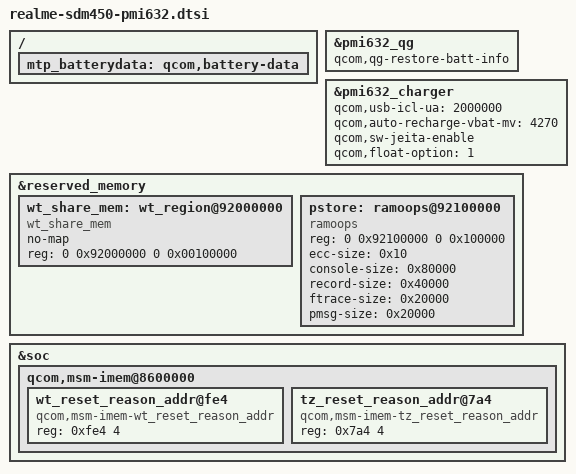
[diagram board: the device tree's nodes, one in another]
/*
 * Copyright (c) 2017-2018, The Linux Foundation. All rights reserved.
 *
 * This program is free software; you can redistribute it and/or modify
 * it under the terms of the GNU General Public License version 2 and
 * only version 2 as published by the Free Software Foundation.
 *
 * This program is distributed in the hope that it will be useful,
 * but WITHOUT ANY WARRANTY; without even the implied warranty of
 * MERCHANTABILITY or FITNESS FOR A PARTICULAR PURPOSE.  See the
 * GNU General Public License for more details.
 */

 /{
	mtp_batterydata: qcom,battery-data {
		#include "battery/qg-batterydata-OPPO-DD003desay-ATL-4v4-4230mAh.dtsi"
		#include "battery/qg-batterydata-OPPO-DD003desay-ATL_300-4v4-4230mAh.dtsi"
		#include "battery/qg-batterydata-OPPO-DD003desay-SDI-4v4-4230mAh.dtsi"
		#include "battery/qg-batterydata-OPPO-DD003desay-SDI_300-4v4-4230mAh.dtsi"
	};
}

&pmi632_qg {
	qcom,qg-restore-batt-info;
};

&pmi632_charger {
	qcom,usb-icl-ua = <2000000>;
	qcom,auto-recharge-vbat-mv = <4270>;
	qcom,sw-jeita-enable;
	qcom,float-option = <1>;
};

&reserved_memory {
	wt_share_mem: wt_region@92000000 {
		compatible = "wt_share_mem";
		no-map;
		reg = <0 0x92000000 0 0x00100000>;
	};

	pstore: ramoops@92100000 {
		compatible = "ramoops";
		reg = <0 0x92100000 0 0x100000>;
		ecc-size	= <0x10>;
		console-size	= <0x80000>;
		record-size	= <0x40000>;
		ftrace-size	= <0x20000>;
		pmsg-size	= <0x20000>;
	};
};

&soc {
	qcom,msm-imem@8600000 {
		wt_reset_reason_addr@fe4 {
			compatible = "qcom,msm-imem-wt_reset_reason_addr";
			reg = <0xfe4 4>;
		};

		tz_reset_reason_addr@7a4 {
			compatible = "qcom,msm-imem-tz_reset_reason_addr";
			reg = <0x7a4 4>;
		};
	};
};
